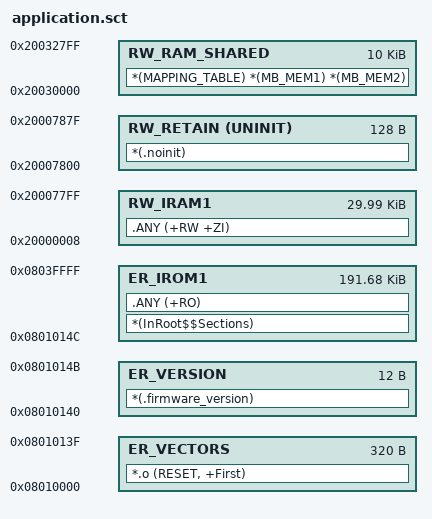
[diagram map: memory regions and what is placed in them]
LR_IROM1 0x8010000 0x30000 {
 ER_VECTORS 0x8010000 0x140 {
  *.o (RESET, +First)
 }
 ER_VERSION 0x8010140 0xc { *(.firmware_version) }
 ER_IROM1 0x801014c 0x2feb4 {
  *(InRoot$$Sections)
  .ANY (+RO)
 }
 RW_RETAIN 0x20007800 UNINIT 0x80 { *(.noinit) }
 RW_IRAM1 0x20000008 0x77F8 { .ANY (+RW +ZI) }
 RW_RAM_SHARED 0x20030000 0x2800 { *(MAPPING_TABLE) *(MB_MEM1) *(MB_MEM2) }
}
